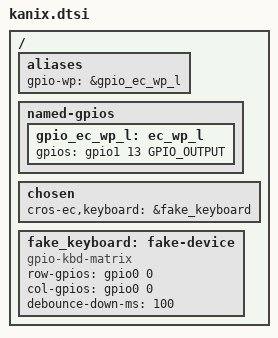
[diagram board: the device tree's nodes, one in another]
/* Copyright 2024 The ChromiumOS Authors
 * Use of this source code is governed by a BSD-style license that can be
 * found in the LICENSE file.
 */

#include "../native_sim.overlay"
#include "../../../../program/rex/kanix/cbi.dtsi"

/ {
	aliases {
		gpio-wp = &gpio_ec_wp_l;
	};

	named-gpios {
		gpio_ec_wp_l: ec_wp_l {
			gpios = <&gpio1 13 GPIO_OUTPUT>;
		};
	};

	chosen {
		cros-ec,keyboard = &fake_keyboard;
	};

	fake_keyboard: fake-device {
		compatible = "gpio-kbd-matrix";
		row-gpios = <&gpio0 0 0>;
		col-gpios = <&gpio0 0 0>;
		debounce-down-ms = <100>;
	};
};
